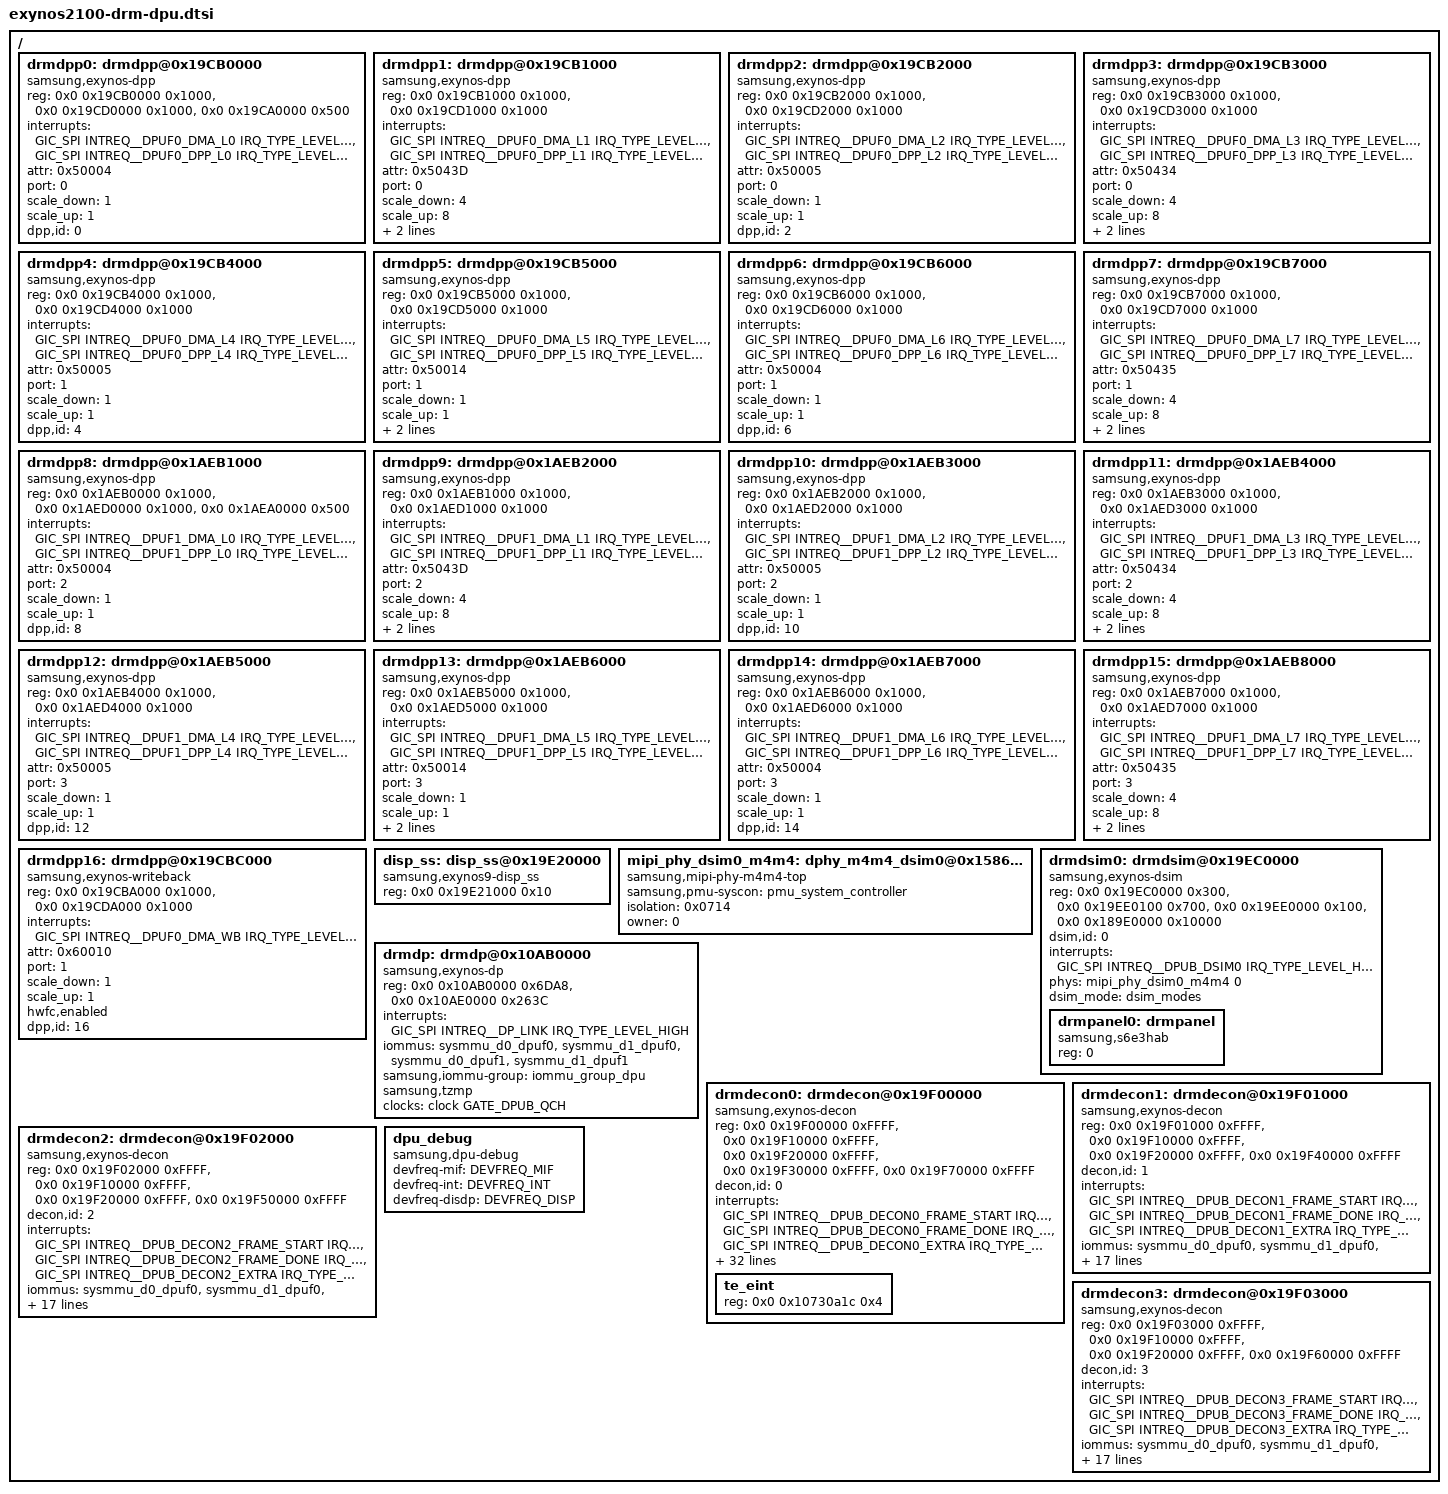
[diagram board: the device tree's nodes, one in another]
/*
 * SAMSUNG EXYNOS2100 SoC device tree source
 *
 * Copyright (c) 2020 Samsung Electronics Co., Ltd.
 *		http://www.samsung.com
 *
 * SAMSUNG EXYNOS9830 SoC device nodes are listed in this file.
 * EXYNOS based board files can include this file and provide
 * values for board specfic bindings.
 *
 * This program is free software; you can redistribute it and/or modify
 * it under the terms of the GNU General Public License version 2 as
 * published by the Free Software Foundation.
 */

#include <dt-bindings/interrupt-controller/arm-gic.h>
#include <dt-bindings/interrupt-controller/exynos2100.h>
#include <dt-bindings/clock/exynos2100.h>
#include <dt-bindings/display/exynos-display.h>
#include "exynos2100-pinctrl.dtsi"
#include "exynos2100-display-timing.dtsi"

/ {
	drmdpp0: drmdpp@0x19CB0000 {	/* L0 */
		compatible = "samsung,exynos-dpp";
		reg = <0x0 0x19CB0000 0x1000>,	/* DPU_DMA */
		      <0x0 0x19CD0000 0x1000>,	/* DPP */
		      <0x0 0x19CA0000 0x500>;	/* vOTF_DPUF0 */
		reg-names = "dma", "dpp", "votf";

		/* DPU_DMA IRQ, DPP IRQ */
		interrupts = <GIC_SPI INTREQ__DPUF0_DMA_L0 IRQ_TYPE_LEVEL_HIGH>,
			   <GIC_SPI INTREQ__DPUF0_DPP_L0 IRQ_TYPE_LEVEL_HIGH>;
		interrupt-names = "dma", "dpp";

		/* Each bit indicates DPP attribute */
		/* 0:AFBC 1:BLOCK 2:FLIP 3:ROT 4:CSC 5:SCALE 6:HDR 7:C_HDR */
		/* 8:C_HDR10 9:WCG 10:SBWC 16:IDMA 17:ODMA 18:DPP */
		attr = <0x50004>;
		port = <0>; /* AXI port number */

		/* 1: scale X, 2: 1/2x scale down, 4: 1/4x scale down */
		scale_down = <1>;
		/* 1: scale X, 2: 2x scale up, 4: 4x scale up */
		scale_up = <1>;

		dpp,id = <0>;
	};

	drmdpp1: drmdpp@0x19CB1000 {	/* L1 */
		compatible = "samsung,exynos-dpp";
		reg = <0x0 0x19CB1000 0x1000>, <0x0 0x19CD1000 0x1000>;
		reg-names = "dma", "dpp";

		interrupts = <GIC_SPI INTREQ__DPUF0_DMA_L1 IRQ_TYPE_LEVEL_HIGH>,
			   <GIC_SPI INTREQ__DPUF0_DPP_L1 IRQ_TYPE_LEVEL_HIGH>;
		interrupt-names = "dma", "dpp";

		attr = <0x5043D>;
		port = <0>;
		scale_down = <4>;
		scale_up = <8>;

		dpp,id = <1>;
		dpp,video;
	};

	drmdpp2: drmdpp@0x19CB2000 {	/* L2 */
		compatible = "samsung,exynos-dpp";
		reg = <0x0 0x19CB2000 0x1000>, <0x0 0x19CD2000 0x1000>;
		reg-names = "dma", "dpp";

		interrupts = <GIC_SPI INTREQ__DPUF0_DMA_L2 IRQ_TYPE_LEVEL_HIGH>,
			   <GIC_SPI INTREQ__DPUF0_DPP_L2 IRQ_TYPE_LEVEL_HIGH>;
		interrupt-names = "dma", "dpp";

		attr = <0x50005>;
		port = <0>;
		scale_down = <1>;
		scale_up = <1>;

		dpp,id = <2>;
	};

	drmdpp3: drmdpp@0x19CB3000 {	/* L3 */
		compatible = "samsung,exynos-dpp";
		reg = <0x0 0x19CB3000 0x1000>, <0x0 0x19CD3000 0x1000>;
		reg-names = "dma", "dpp";

		interrupts = <GIC_SPI INTREQ__DPUF0_DMA_L3 IRQ_TYPE_LEVEL_HIGH>,
			   <GIC_SPI INTREQ__DPUF0_DPP_L3 IRQ_TYPE_LEVEL_HIGH>;
		interrupt-names = "dma", "dpp";

		attr = <0x50434>;
		port = <0>;
		scale_down = <4>;
		scale_up = <8>;

		dpp,id = <3>;
		dpp,video;
	};

	drmdpp4: drmdpp@0x19CB4000 {	/* L4 */
		compatible = "samsung,exynos-dpp";
		reg = <0x0 0x19CB4000 0x1000>, <0x0 0x19CD4000 0x1000>;
		reg-names = "dma", "dpp";

		interrupts = <GIC_SPI INTREQ__DPUF0_DMA_L4 IRQ_TYPE_LEVEL_HIGH>,
			   <GIC_SPI INTREQ__DPUF0_DPP_L4 IRQ_TYPE_LEVEL_HIGH>;
		interrupt-names = "dma", "dpp";

		attr = <0x50005>;
		port = <1>;
		scale_down = <1>;
		scale_up = <1>;

		dpp,id = <4>;
	};

	drmdpp5: drmdpp@0x19CB5000 {	/* L5 */
		compatible = "samsung,exynos-dpp";
		reg = <0x0 0x19CB5000 0x1000>, <0x0 0x19CD5000 0x1000>;
		reg-names = "dma", "dpp";

		interrupts = <GIC_SPI INTREQ__DPUF0_DMA_L5 IRQ_TYPE_LEVEL_HIGH>,
			   <GIC_SPI INTREQ__DPUF0_DPP_L5 IRQ_TYPE_LEVEL_HIGH>;
		interrupt-names = "dma", "dpp";

		attr = <0x50014>;
		port = <1>;
		scale_down = <1>;
		scale_up = <1>;

		dpp,id = <5>;
		dpp,video;
	};

	drmdpp6: drmdpp@0x19CB6000 {	/* L6 */
		compatible = "samsung,exynos-dpp";
		reg = <0x0 0x19CB6000 0x1000>, <0x0 0x19CD6000 0x1000>;
		reg-names = "dma", "dpp";

		interrupts = <GIC_SPI INTREQ__DPUF0_DMA_L6 IRQ_TYPE_LEVEL_HIGH>,
			   <GIC_SPI INTREQ__DPUF0_DPP_L6 IRQ_TYPE_LEVEL_HIGH>;
		interrupt-names = "dma", "dpp";

		attr = <0x50004>;
		port = <1>;
		scale_down = <1>;
		scale_up = <1>;

		dpp,id = <6>;
	};

	drmdpp7: drmdpp@0x19CB7000 {	/* L7 */
		compatible = "samsung,exynos-dpp";
		reg = <0x0 0x19CB7000 0x1000>, <0x0 0x19CD7000 0x1000>;
		reg-names = "dma", "dpp";

		interrupts = <GIC_SPI INTREQ__DPUF0_DMA_L7 IRQ_TYPE_LEVEL_HIGH>,
			   <GIC_SPI INTREQ__DPUF0_DPP_L7 IRQ_TYPE_LEVEL_HIGH>;
		interrupt-names = "dma", "dpp";

		attr = <0x50435>;
		port = <1>;
		scale_down = <4>;
		scale_up = <8>;

		dpp,id = <7>;
		dpp,video;
	};

	drmdpp8: drmdpp@0x1AEB1000 {	/* L8 */
		compatible = "samsung,exynos-dpp";
		reg = <0x0 0x1AEB0000 0x1000>, <0x0 0x1AED0000 0x1000>,
		    <0x0 0x1AEA0000 0x500>;
		reg-names = "dma", "dpp", "votf";

		interrupts = <GIC_SPI INTREQ__DPUF1_DMA_L0 IRQ_TYPE_LEVEL_HIGH>,
			   <GIC_SPI INTREQ__DPUF1_DPP_L0 IRQ_TYPE_LEVEL_HIGH>;
		interrupt-names = "dma", "dpp";

		attr = <0x50004>;
		port = <2>;
		scale_down = <1>;
		scale_up = <1>;

		dpp,id = <8>;
	};

	drmdpp9: drmdpp@0x1AEB2000 {	/* L9 */
		compatible = "samsung,exynos-dpp";
		reg = <0x0 0x1AEB1000 0x1000>, <0x0 0x1AED1000 0x1000>;
		reg-names = "dma", "dpp";

		interrupts = <GIC_SPI INTREQ__DPUF1_DMA_L1 IRQ_TYPE_LEVEL_HIGH>,
			   <GIC_SPI INTREQ__DPUF1_DPP_L1 IRQ_TYPE_LEVEL_HIGH>;
		interrupt-names = "dma", "dpp";

		attr = <0x5043D>;
		port = <2>;
		scale_down = <4>;
		scale_up = <8>;

		dpp,id = <9>;
		dpp,video;
	};

	drmdpp10: drmdpp@0x1AEB3000 {	/* L10 */
		compatible = "samsung,exynos-dpp";
		reg = <0x0 0x1AEB2000 0x1000>, <0x0 0x1AED2000 0x1000>;
		reg-names = "dma", "dpp";

		interrupts = <GIC_SPI INTREQ__DPUF1_DMA_L2 IRQ_TYPE_LEVEL_HIGH>,
			   <GIC_SPI INTREQ__DPUF1_DPP_L2 IRQ_TYPE_LEVEL_HIGH>;
		interrupt-names = "dma", "dpp";

		attr = <0x50005>;
		port = <2>;
		scale_down = <1>;
		scale_up = <1>;

		dpp,id = <10>;
	};

	drmdpp11: drmdpp@0x1AEB4000 {	/* L11 */
		compatible = "samsung,exynos-dpp";
		reg = <0x0 0x1AEB3000 0x1000>, <0x0 0x1AED3000 0x1000>;
		reg-names = "dma", "dpp";

		interrupts = <GIC_SPI INTREQ__DPUF1_DMA_L3 IRQ_TYPE_LEVEL_HIGH>,
			   <GIC_SPI INTREQ__DPUF1_DPP_L3 IRQ_TYPE_LEVEL_HIGH>;
		interrupt-names = "dma", "dpp";

		attr = <0x50434>;
		port = <2>;
		scale_down = <4>;
		scale_up = <8>;

		dpp,id = <11>;
		dpp,video;
	};

	drmdpp12: drmdpp@0x1AEB5000 {	/* L12 */
		compatible = "samsung,exynos-dpp";
		reg = <0x0 0x1AEB4000 0x1000>, <0x0 0x1AED4000 0x1000>;
		reg-names = "dma", "dpp";

		interrupts = <GIC_SPI INTREQ__DPUF1_DMA_L4 IRQ_TYPE_LEVEL_HIGH>,
			   <GIC_SPI INTREQ__DPUF1_DPP_L4 IRQ_TYPE_LEVEL_HIGH>;
		interrupt-names = "dma", "dpp";

		attr = <0x50005>;
		port = <3>;
		scale_down = <1>;
		scale_up = <1>;

		dpp,id = <12>;
	};

	drmdpp13: drmdpp@0x1AEB6000 {	/* L13 */
		compatible = "samsung,exynos-dpp";
		reg = <0x0 0x1AEB5000 0x1000>, <0x0 0x1AED5000 0x1000>;
		reg-names = "dma", "dpp";

		interrupts = <GIC_SPI INTREQ__DPUF1_DMA_L5 IRQ_TYPE_LEVEL_HIGH>,
			   <GIC_SPI INTREQ__DPUF1_DPP_L5 IRQ_TYPE_LEVEL_HIGH>;
		interrupt-names = "dma", "dpp";

		attr = <0x50014>;
		port = <3>;
		scale_down = <1>;
		scale_up = <1>;

		dpp,id = <13>;
		dpp,video;
	};

	drmdpp14: drmdpp@0x1AEB7000 {	/* L14 */
		compatible = "samsung,exynos-dpp";
		reg = <0x0 0x1AEB6000 0x1000>, <0x0 0x1AED6000 0x1000>;
		reg-names = "dma", "dpp";

		interrupts = <GIC_SPI INTREQ__DPUF1_DMA_L6 IRQ_TYPE_LEVEL_HIGH>,
			   <GIC_SPI INTREQ__DPUF1_DPP_L6 IRQ_TYPE_LEVEL_HIGH>;
		interrupt-names = "dma", "dpp";

		/* DPP[18]/IDMA[16]/CSC[4]/FLIP[2]/BLOCK[1]/AFBC[0] */
		attr = <0x50004>;
		port = <3>;
		scale_down = <1>;
		scale_up = <1>;

		dpp,id = <14>;
	};

	drmdpp15: drmdpp@0x1AEB8000 {	/* L15 */
		compatible = "samsung,exynos-dpp";
		reg = <0x0 0x1AEB7000 0x1000>, <0x0 0x1AED7000 0x1000>;
		reg-names = "dma", "dpp";

		interrupts = <GIC_SPI INTREQ__DPUF1_DMA_L7 IRQ_TYPE_LEVEL_HIGH>,
			   <GIC_SPI INTREQ__DPUF1_DPP_L7 IRQ_TYPE_LEVEL_HIGH>;
		interrupt-names = "dma", "dpp";

		attr = <0x50435>;
		port = <3>;
		scale_down = <4>;
		scale_up = <8>;

		dpp,id = <15>;
		dpp,video;
	};

	drmdpp16: drmdpp@0x19CBC000 {
		compatible = "samsung,exynos-writeback";
		reg = <0x0 0x19CBA000 0x1000>, <0x0 0x19CDA000 0x1000>;
		reg-names = "dma", "dpp";

		interrupts = <GIC_SPI INTREQ__DPUF0_DMA_WB IRQ_TYPE_LEVEL_HIGH>;
		interrupt-names = "dma";

		attr = <0x60010>;
		port = <1>;
		scale_down = <1>;
		scale_up = <1>;

		hwfc,enabled;

		dpp,id = <16>;
	};

	//dma_dsimfc_0: fcmd@0x19CBC000 {	/* DPUF0_DSIMFC_L0 */
		//compatible = "samsung,exynos9-fcmd";
		///* DPU_DMA */
		//reg = <0x0 0x19CBC000 0x1000>;
		/* DPU_DMA IRQ */
		//interrupts = <GIC_SPI INTREQ__DPUF0_DMA_DSIMFC0 IRQ_TYPE_LEVEL_HIGH>;
		//port = <0>; /* AXI port number */
	//};

	//dma_dsimfc_1: fcmd@0x19CBD000 {	/* DPUF0_DSIMFC_L1 */
		//compatible = "samsung,exynos9-fcmd";
		///* DPU_DMA */
		//reg = <0x0 0x19CBD000 0x1000>;
		///* DPU_DMA IRQ */
		//interrupts = <GIC_SPI INTREQ__DPUF0_DMA_DSIMFC1 IRQ_TYPE_LEVEL_HIGH>;
		//port = <1>; /* AXI port number */
	//};

	//dma_dsimfc_2: fcmd@0x1AEBC000 {	/* DPUF1_DSIMFC_L2 */
		//compatible = "samsung,exynos9-fcmd";
		///* DPU_DMA */
		//reg = <0x0 0x1AEBC000 0x1000>;
		///* DPU_DMA IRQ */
		//interrupts = <GIC_SPI INTREQ__DPUF1_DMA_DSIMFC0 IRQ_TYPE_LEVEL_HIGH>;
		//port = <2>; /* AXI port number */
	//};

	disp_ss: disp_ss@0x19E20000 {
		compatible = "samsung,exynos9-disp_ss";
		reg = <0x0 0x19E21000 0x10>;
		reg-names = "sys";
	};

	mipi_phy_dsim0_m4m4: dphy_m4m4_dsim0@0x15860000 {
		compatible = "samsung,mipi-phy-m4m4-top";
		samsung,pmu-syscon = <&pmu_system_controller>; /* TODO FIXUP */
		isolation = <0x0714>;
		owner = <0>; /* 0: DSI_0 1: DSI_1 */
		#phy-cells = <1>;
	};

	drmdsim0: drmdsim@0x19EC0000 {
		compatible = "samsung,exynos-dsim";
		reg = <0x0 0x19EC0000 0x300>,	/* DSIM0 */
		      <0x0 0x19EE0100 0x700>,	/* DCPHY_M4M4_TOP */
		      <0x0 0x19EE0000 0x100>,	/* DCPHY_M4M4_COMMON */
		      <0x0 0x189E0000 0x10000>;	/* vOTF_MSCL(for vOTF sysmmu) */
		reg-names = "dsi", "dphy", "dphy-extra", "votf";

		dsim,id = <0>;

		interrupts = <GIC_SPI INTREQ__DPUB_DSIM0 IRQ_TYPE_LEVEL_HIGH>;
		interrupt-names = "dsim";

		phys = <&mipi_phy_dsim0_m4m4 0>;
		phy-names = "dsim_dphy";

		dsim_mode = <&dsim_modes>;

		#address-cells = <1>;
		#size-cells = <0>;

		drmpanel0: drmpanel {
			compatible = "samsung,s6e3hab";
			reg = <0>;

			/* TODO: fix up */
			/* reset, power */
			//reset-gpios = <&gpp24 1 GPIO_ACTIVE_HIGH>;
			//vci-supply = <&m_ldo22_reg>;
			//vddi-supply = <&m_ldo30_reg>;
		};
	};

	drmdp: drmdp@0x10AB0000 {
		compatible = "samsung,exynos-dp";
		reg = <0x0 0x10AB0000 0x6DA8>,
			<0x0 0x10AE0000 0x263C>;
		interrupts = <GIC_SPI INTREQ__DP_LINK IRQ_TYPE_LEVEL_HIGH>;
		iommus = <&sysmmu_d0_dpuf0>, <&sysmmu_d1_dpuf0>, <&sysmmu_d0_dpuf1>, <&sysmmu_d1_dpuf1>;
		samsung,iommu-group = <&iommu_group_dpu>;

		/* To use secure buffer address range. If you not set this, normal buffer is transfered on DRM scenario */
		samsung,tzmp;

		/* clock */
		clock-names = "aclk";
		clocks = <&clock GATE_DPUB_QCH>;
	};

	drmdecon0: drmdecon@0x19F00000 {
		compatible = "samsung,exynos-decon";
		reg = <0x0 0x19F00000 0xFFFF>,	/* DECON0_MAIN */
		      <0x0 0x19F10000 0xFFFF>,	/* DECON_WIN */
		      <0x0 0x19F20000 0xFFFF>,	/* DECON_SUB */
		      <0x0 0x19F30000 0xFFFF>,	/* DECON0_WINCON */
		      <0x0 0x19F70000 0xFFFF>;	/* DQE */
		reg-names = "main", "win", "sub", "wincon", "dqe";

		decon,id = <0>;

		interrupts = <GIC_SPI INTREQ__DPUB_DECON0_FRAME_START
				IRQ_TYPE_LEVEL_HIGH>,
			     <GIC_SPI INTREQ__DPUB_DECON0_FRAME_DONE
				IRQ_TYPE_LEVEL_HIGH>,
			     <GIC_SPI INTREQ__DPUB_DECON0_EXTRA
				IRQ_TYPE_LEVEL_HIGH>;
		interrupt-names = "frame_start", "frame_done", "extra";

		iommus = <&sysmmu_d0_dpuf0>, <&sysmmu_d1_dpuf0>,
		         <&sysmmu_d0_dpuf1>, <&sysmmu_d1_dpuf1>;
		samsung,iommu-group = <&iommu_group_dpu>;
		/* To use secure buffer address range. If you not set this, */
		/* normal buffer is transfered on DRM scenario */
		samsung,tzmp;

		/* clock */
		clock-names = "aclk";
		clocks = <&clock GATE_DPUB_QCH>;

		/* pinctrl */
		pinctrl-names = "hw_te_on", "hw_te_off";
		pinctrl-0 = <&decon_0_te_on>;
		pinctrl-1 = <&decon_0_te_off>;

		max_win = <16>;
		/* 0: video mode, 1: MIPI command mode 2: DP command mode */
		op_mode = <1>;
		trig_mode = <0>;   /* 0: hw trigger, 1: sw trigger */
		out_type = <0x1>; /* BIT0:DSI0, BIT1:DSI1, BIT4:DP0, BIT5:DP1 */

		/* 0: from DDI0, 1: from DDI1, 2: from DDI2 3: not receive TE */
		te_from = <0>;

		/* BTS */ /* TODO: check olympus */
		ppc = <2>;			/* pixel per clock */
		line_mem_cnt = <4>;
		cycle_per_line = <8>;		/* 4ppc */

		/* Urgent */
		rd_en = <0>; /* defaultly disable */
		rd_hi_thres = <0x800>;
		rd_lo_thres = <0x400>;
		rd_wait_cycle = <0x10>;
		wr_en = <0>; /* defaultly disable */
		wr_hi_thres = <0x0>;
		wr_lo_thres = <0x0>;

		/* DTA */
		dta_en = <0>; /* defaultly disable */
		dta_hi_thres = <0x3200>;
		dta_lo_thres = <0x600>;

		/* EINT for TE */
		gpios = <&gpg1 4 0xf>;

		dpps = <&drmdpp0 &drmdpp1 &drmdpp2 &drmdpp3 &drmdpp4 &drmdpp5
			&drmdpp6 &drmdpp7 &drmdpp8 &drmdpp9 &drmdpp10
			&drmdpp11 &drmdpp12 &drmdpp13 &drmdpp14	&drmdpp15>;

		/*
		 * connector type that can be connected to the DECON. please
		 * refer to enum exynos_drm_output_type in exynos_drm_drv.h
		 *
		 * DSI0(0x1), DSI1(0x2), VIDI(0x8)
		 */
		connector = <0x1 0x2 0x8>;

		hibernation;

		#address-cells = <2>;
		#size-cells = <1>;
		ranges;

		/* sw te pending register */
		te_eint {
			/* NWEINT_GPG1_PEND */
			reg = <0x0 0x10730a1c 0x4>;
		};
	};

	drmdecon1: drmdecon@0x19F01000 {
		compatible = "samsung,exynos-decon";
		reg = <0x0 0x19F01000 0xFFFF>,	/* DECON0_MAIN */
		      <0x0 0x19F10000 0xFFFF>,	/* DECON_WIN */
		      <0x0 0x19F20000 0xFFFF>,	/* DECON_SUB */
		      <0x0 0x19F40000 0xFFFF>;	/* DECON0_WINCON */
		reg-names = "main", "win", "sub", "wincon";

		decon,id = <1>;

		interrupts = <GIC_SPI INTREQ__DPUB_DECON1_FRAME_START
				IRQ_TYPE_LEVEL_HIGH>,
			     <GIC_SPI INTREQ__DPUB_DECON1_FRAME_DONE
				IRQ_TYPE_LEVEL_HIGH>,
			     <GIC_SPI INTREQ__DPUB_DECON1_EXTRA
				IRQ_TYPE_LEVEL_HIGH>;
		interrupt-names = "frame_start", "frame_done", "extra";

		iommus = <&sysmmu_d0_dpuf0>, <&sysmmu_d1_dpuf0>,
		         <&sysmmu_d0_dpuf1>, <&sysmmu_d1_dpuf1>;
		samsung,iommu-group = <&iommu_group_dpu>;
		samsung,tzmp;

		/* clock */
		clock-names = "aclk";
		clocks = <&clock GATE_DPUB_QCH>;

		max_win = <16>;
		op_mode = <1>;
		trig_mode = <1>;	/* 0: hw trigger, 1: sw trigger */
		out_type = <0x100>;	/* BIT8: WB */

		te_from = <0>;

		/* BTS */ /* TODO: check olympus */
		ppc = <2>;		/* pixel per clock */
		line_mem_cnt = <4>;
		cycle_per_line = <8>;   /* 4ppc */

		dpps = <&drmdpp0 &drmdpp1 &drmdpp2 &drmdpp3 &drmdpp4 &drmdpp5
			&drmdpp6 &drmdpp7 &drmdpp8 &drmdpp9 &drmdpp10
			&drmdpp11 &drmdpp12 &drmdpp13 &drmdpp14	&drmdpp15>;
		connector = <0x8>;
	};

	drmdecon2: drmdecon@0x19F02000 {
		compatible = "samsung,exynos-decon";
		reg = <0x0 0x19F02000 0xFFFF>,
		      <0x0 0x19F10000 0xFFFF>,
		      <0x0 0x19F20000 0xFFFF>,
		      <0x0 0x19F50000 0xFFFF>;
		reg-names = "main", "win", "sub", "wincon";

		decon,id = <2>;

		interrupts = <GIC_SPI INTREQ__DPUB_DECON2_FRAME_START
				IRQ_TYPE_LEVEL_HIGH>,
			     <GIC_SPI INTREQ__DPUB_DECON2_FRAME_DONE
				IRQ_TYPE_LEVEL_HIGH>,
			     <GIC_SPI INTREQ__DPUB_DECON2_EXTRA
				IRQ_TYPE_LEVEL_HIGH>;
		interrupt-names = "frame_start", "frame_done", "extra";

		iommus = <&sysmmu_d0_dpuf0>, <&sysmmu_d1_dpuf0>,
		         <&sysmmu_d0_dpuf1>, <&sysmmu_d1_dpuf1>;
		samsung,iommu-group = <&iommu_group_dpu>;
		samsung,tzmp;

		/* clock */
		clock-names = "aclk";
		clocks = <&clock GATE_DPUB_QCH>;

		max_win = <16>;
		op_mode = <0>;
		trig_mode = <0>;        /* 0: hw trigger, 1: sw trigger */
		out_type = <0x10>;/* BIT0:DSI0, BIT1:DSI1, BIT4:DP0, BIT5:DP1 */

		te_from = <0>;

		ppc = <2>;			/* pixel per clock */
		line_mem_cnt = <4>;
		cycle_per_line = <8>;		/* 4ppc */

		dpps = <&drmdpp0 &drmdpp1 &drmdpp2 &drmdpp3 &drmdpp4 &drmdpp5
			&drmdpp6 &drmdpp7 &drmdpp8 &drmdpp9 &drmdpp10
			&drmdpp11 &drmdpp12 &drmdpp13 &drmdpp14	&drmdpp15>;
		/* TODO: FIX for DP */
		connector = <0x10>;
	};

	drmdecon3: drmdecon@0x19F03000 {
		compatible = "samsung,exynos-decon";
		reg = <0x0 0x19F03000 0xFFFF>,
		      <0x0 0x19F10000 0xFFFF>,
		      <0x0 0x19F20000 0xFFFF>,
		      <0x0 0x19F60000 0xFFFF>;
		reg-names = "main", "win", "sub", "wincon";

		decon,id = <3>;

		/* interrupt num : FRAME_START, FRMAE_DONE, EXTRA */
		interrupts = <GIC_SPI INTREQ__DPUB_DECON3_FRAME_START
				IRQ_TYPE_LEVEL_HIGH>,
			     <GIC_SPI INTREQ__DPUB_DECON3_FRAME_DONE
				IRQ_TYPE_LEVEL_HIGH>,
			     <GIC_SPI INTREQ__DPUB_DECON3_EXTRA
				IRQ_TYPE_LEVEL_HIGH>;
		interrupt-names = "frame_start", "frame_done", "extra";

		iommus = <&sysmmu_d0_dpuf0>, <&sysmmu_d1_dpuf0>,
		         <&sysmmu_d0_dpuf1>, <&sysmmu_d1_dpuf1>;
		samsung,iommu-group = <&iommu_group_dpu>;
		samsung,tzmp;

		/* clock */
		clock-names = "aclk";
		clocks = <&clock GATE_DPUB_QCH>;

		max_win = <16>;
		op_mode = <0>;
		trig_mode = <0>;        /* 0: hw trigger, 1: sw trigger */
		out_type = <0x10>;/* BIT0:DSI0, BIT1:DSI1, BIT4:DP0, BIT5:DP1 */

		te_from = <0>;

		ppc = <2>;			/* pixel per clock */
		line_mem_cnt = <4>;
		cycle_per_line = <8>;		/* 4ppc */

		dpps = <&drmdpp0 &drmdpp1 &drmdpp2 &drmdpp3 &drmdpp4 &drmdpp5
			&drmdpp6 &drmdpp7 &drmdpp8 &drmdpp9 &drmdpp10
			&drmdpp11 &drmdpp12 &drmdpp13 &drmdpp14	&drmdpp15>;
		/* TODO: FIX for DP */
		connector = <0x100>;
	};

	dpu_debug{
		compatible = "samsung,dpu-debug";
		devfreq-mif = <DEVFREQ_MIF>;
		devfreq-int = <DEVFREQ_INT>;
		devfreq-disdp = <DEVFREQ_DISP>;
	};
};
